# iostr912fa register map
Registers are 32-bit, access not given, no defined reset value unless marked. A register's access mark holds for its fields unless they carry their own. Addresses are absolute; registers are grouped by the start of their names; [hi:lo] are bit positions; {n}, {i} and the like mark numbered series; 'fields as' and 'values as' point back to an identical list.

## WIU
0x48001000 WIU_CTRL_BUF
  [1] INT_EN
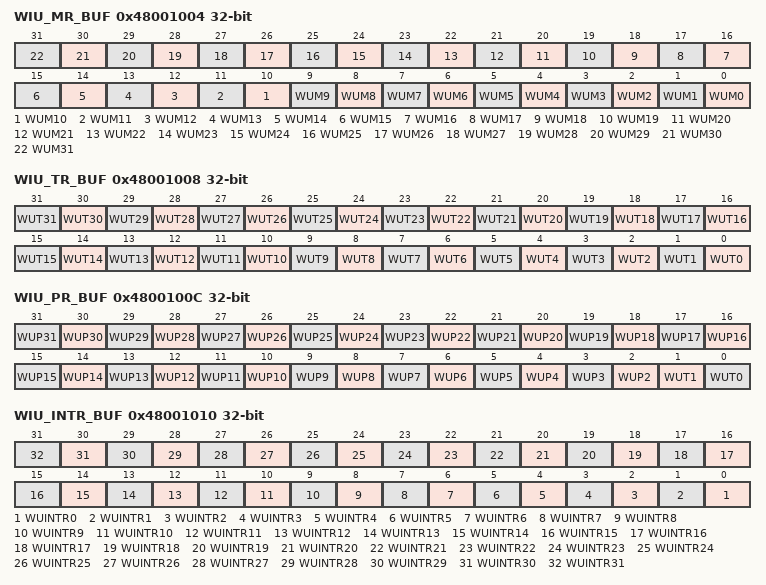
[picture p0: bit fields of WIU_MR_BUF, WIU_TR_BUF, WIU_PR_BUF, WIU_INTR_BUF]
0x48001004 WIU_MR_BUF
  [n] WUM{n} (n=0..31)
0x48001008 WIU_TR_BUF
  [n] WUT{n} (n=0..31)
0x4800100C WIU_PR_BUF
  [n] WUP{n} (n=2..31), [1] WUT1, [0] WUT0
0x48001010 WIU_INTR_BUF
  [n] WUINTR{n} (n=0..31)
0x58001000 WIU_CTRL
  [1] INT_EN
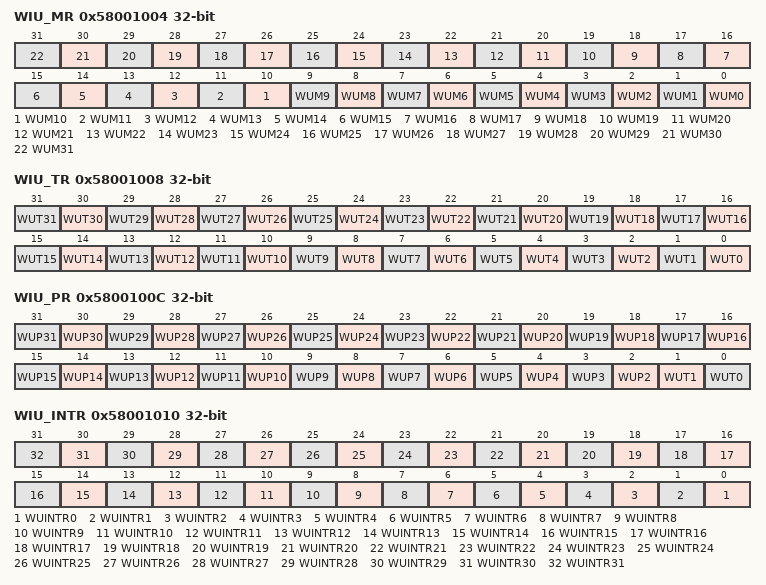
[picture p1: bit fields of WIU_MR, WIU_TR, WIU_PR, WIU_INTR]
0x58001004 WIU_MR
  [n] WUM{n} (n=0..31)
0x58001008 WIU_TR
  [n] WUT{n} (n=0..31)
0x5800100C WIU_PR
  [n] WUP{n} (n=2..31), [1] WUT1, [0] WUT0
0x58001010 WIU_INTR
  [n] WUINTR{n} (n=0..31)

## RTC
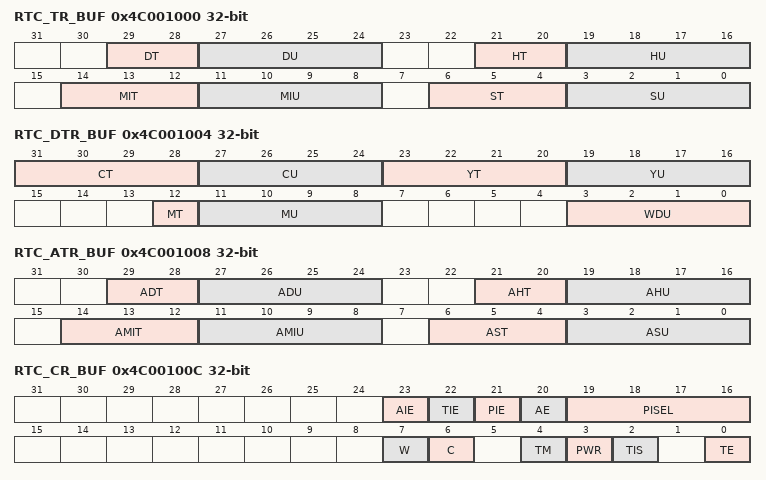
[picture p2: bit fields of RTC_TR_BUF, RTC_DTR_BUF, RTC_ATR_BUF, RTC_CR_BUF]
0x4C001000 RTC_TR_BUF
  [29:28] DT, [27:24] DU, [21:20] HT, [19:16] HU, [14:12] MIT, [11:8] MIU, [6:4] ST, [3:0] SU
0x4C001004 RTC_DTR_BUF
  [31:28] CT, [27:24] CU, [23:20] YT, [19:16] YU, [12] MT, [11:8] MU, [3:0] WDU
0x4C001008 RTC_ATR_BUF
  [29:28] ADT, [27:24] ADU, [21:20] AHT, [19:16] AHU, [14:12] AMIT, [11:8] AMIU, [6:4] AST, [3:0] ASU
0x4C00100C RTC_CR_BUF
  [23] AIE, [22] TIE, [21] PIE, [20] AE, [19:16] PISEL, [7] W, [6] C, [4] TM, [3] PWR, [2] TIS, [0] TE
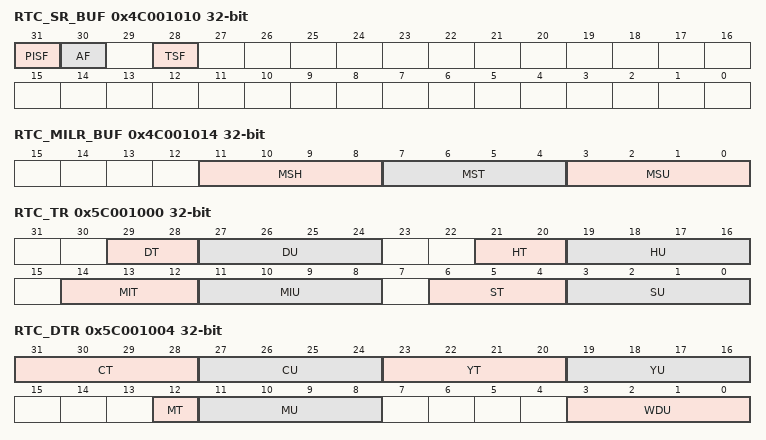
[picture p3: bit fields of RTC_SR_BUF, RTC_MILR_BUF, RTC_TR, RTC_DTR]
0x4C001010 RTC_SR_BUF
  [31] PISF, [30] AF, [28] TSF
0x4C001014 RTC_MILR_BUF
  [11:8] MSH, [7:4] MST, [3:0] MSU
0x5C001000 RTC_TR
  fields as RTC_TR_BUF
0x5C001004 RTC_DTR
  fields as RTC_DTR_BUF
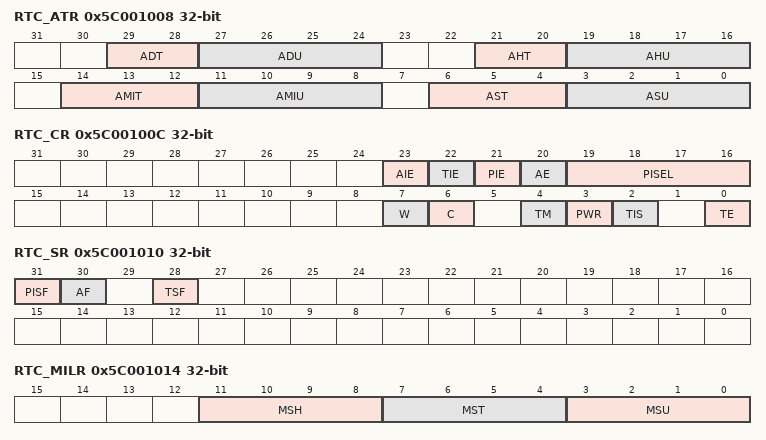
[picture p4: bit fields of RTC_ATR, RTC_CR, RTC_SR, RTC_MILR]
0x5C001008 RTC_ATR
  fields as RTC_ATR_BUF
0x5C00100C RTC_CR
  fields as RTC_CR_BUF
0x5C001010 RTC_SR
  [31] PISF, [30] AF, [28] TSF
0x5C001014 RTC_MILR
  [11:8] MSH, [7:4] MST, [3:0] MSU

## WDG
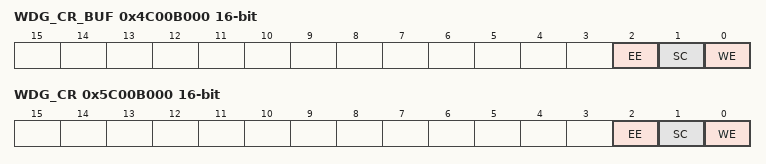
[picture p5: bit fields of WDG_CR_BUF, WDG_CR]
0x4C00B000 WDG_CR_BUF 16-bit
  [2] EE, [1] SC, [0] WE
0x4C00B004 WDG_PR_BUF 8-bit
0x4C00B008 WDG_VR_BUF 16-bit
0x4C00B00C WDG_CNT_BUF 16-bit
0x4C00B010 WDG_SR_BUF 16-bit
  [0] EC
0x4C00B014 WDG_MR_BUF 16-bit
  [0] ECM
0x4C00B018 WDG_KR_BUF 16-bit
0x5C00B000 WDG_CR 16-bit
  [2] EE, [1] SC, [0] WE
0x5C00B004 WDG_PR 8-bit
0x5C00B008 WDG_VR 16-bit
0x5C00B00C WDG_CNT 16-bit
0x5C00B010 WDG_SR 16-bit
  [0] EC
0x5C00B014 WDG_MR 16-bit
  [0] ECM
0x5C00B018 WDG_KR 16-bit

## TIM0
0x48002000 TIM0_IC1R_BUF 16-bit
0x48002004 TIM0_IC2R_BUF 16-bit
0x48002008 TIM0_OC1R_BUF 16-bit
0x4800200C TIM0_OC2R_BUF 16-bit
0x48002010 TIM0_CNTR_BUF 16-bit
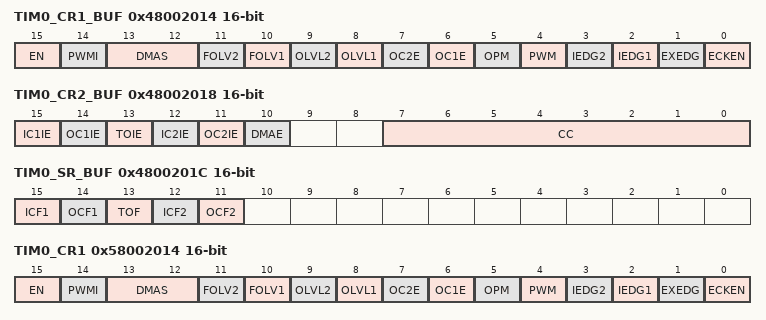
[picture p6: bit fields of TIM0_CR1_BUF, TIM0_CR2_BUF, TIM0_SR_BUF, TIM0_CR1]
0x48002014 TIM0_CR1_BUF 16-bit
  [15] EN, [14] PWMI, [13:12] DMAS, [11] FOLV2, [10] FOLV1, [9] OLVL2, [8] OLVL1, [7] OC2E, [6] OC1E, [5] OPM, [4] PWM, [3] IEDG2, [2] IEDG1, [1] EXEDG, [0] ECKEN
0x48002018 TIM0_CR2_BUF 16-bit
  [15] IC1IE, [14] OC1IE, [13] TOIE, [12] IC2IE, [11] OC2IE, [10] DMAE, [7:0] CC
0x4800201C TIM0_SR_BUF 16-bit
  [15] ICF1, [14] OCF1, [13] TOF, [12] ICF2, [11] OCF2
0x58002000 TIM0_IC1R 16-bit
0x58002004 TIM0_IC2R 16-bit
0x58002008 TIM0_OC1R 16-bit
0x5800200C TIM0_OC2R 16-bit
0x58002010 TIM0_CNTR 16-bit
0x58002014 TIM0_CR1 16-bit
  fields as TIM0_CR1_BUF
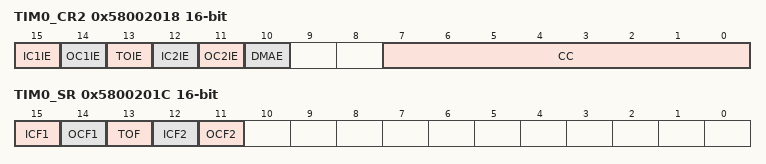
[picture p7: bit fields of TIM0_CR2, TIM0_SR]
0x58002018 TIM0_CR2 16-bit
  fields as TIM0_CR2_BUF
0x5800201C TIM0_SR 16-bit
  [15] ICF1, [14] OCF1, [13] TOF, [12] ICF2, [11] OCF2

## TIM1
0x48003000 TIM1_IC1R_BUF 16-bit
0x48003004 TIM1_IC2R_BUF 16-bit
0x48003008 TIM1_OC1R_BUF 16-bit
0x4800300C TIM1_OC2R_BUF 16-bit
0x48003010 TIM1_CNTR_BUF 16-bit
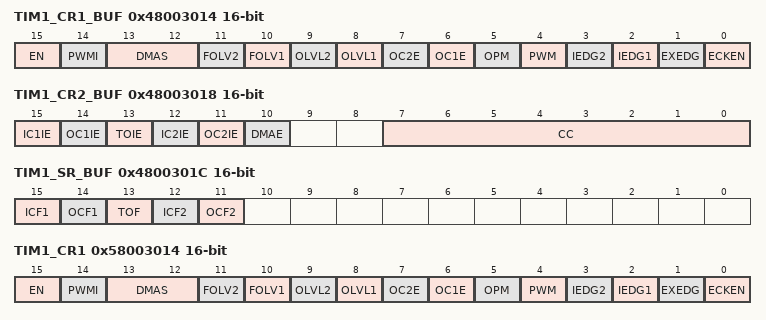
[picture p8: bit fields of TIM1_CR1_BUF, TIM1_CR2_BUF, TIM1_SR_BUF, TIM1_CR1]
0x48003014 TIM1_CR1_BUF 16-bit
  [15] EN, [14] PWMI, [13:12] DMAS, [11] FOLV2, [10] FOLV1, [9] OLVL2, [8] OLVL1, [7] OC2E, [6] OC1E, [5] OPM, [4] PWM, [3] IEDG2, [2] IEDG1, [1] EXEDG, [0] ECKEN
0x48003018 TIM1_CR2_BUF 16-bit
  [15] IC1IE, [14] OC1IE, [13] TOIE, [12] IC2IE, [11] OC2IE, [10] DMAE, [7:0] CC
0x4800301C TIM1_SR_BUF 16-bit
  [15] ICF1, [14] OCF1, [13] TOF, [12] ICF2, [11] OCF2
0x58003000 TIM1_IC1R 16-bit
0x58003004 TIM1_IC2R 16-bit
0x58003008 TIM1_OC1R 16-bit
0x5800300C TIM1_OC2R 16-bit
0x58003010 TIM1_CNTR 16-bit
0x58003014 TIM1_CR1 16-bit
  fields as TIM1_CR1_BUF
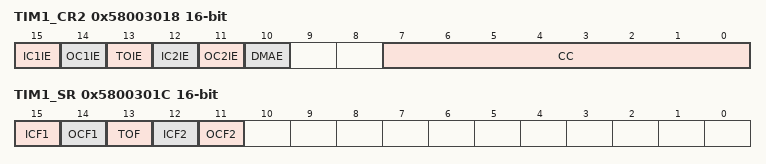
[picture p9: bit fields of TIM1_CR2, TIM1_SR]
0x58003018 TIM1_CR2 16-bit
  fields as TIM1_CR2_BUF
0x5800301C TIM1_SR 16-bit
  [15] ICF1, [14] OCF1, [13] TOF, [12] ICF2, [11] OCF2
